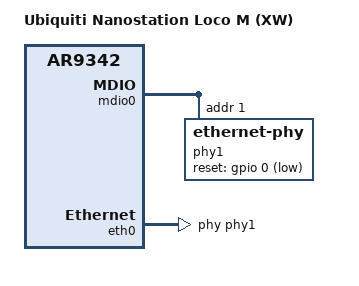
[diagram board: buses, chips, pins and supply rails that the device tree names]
// SPDX-License-Identifier: GPL-2.0-or-later OR MIT

#include "ar9342_ubnt_xw.dtsi"

/ {
	compatible = "ubnt,nanostation-loco-m-xw", "ubnt,xw", "qca,ar9342";
	model = "Ubiquiti Nanostation Loco M (XW)";
};

&mdio0 {
	status = "okay";

	phy-mask = <0x1>;

	phy1: ethernet-phy@1 {
		reg = <1>;
		phy-mode = "mii";
		reset-gpios = <&gpio 0 GPIO_ACTIVE_LOW>;
	};
};

&eth0 {
	status = "okay";

	phy-handle = <&phy1>;
};
